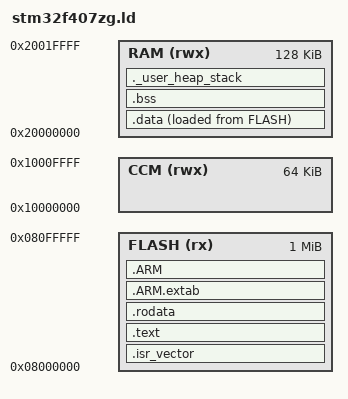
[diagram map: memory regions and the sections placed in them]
/* 仅用于 .simtest 交叉编译验证的链接脚本（STM32F407ZGT6: 1M Flash / 192K RAM） */
ENTRY(Reset_Handler)

MEMORY
{
  FLASH (rx)  : ORIGIN = 0x08000000, LENGTH = 1024K
  RAM   (rwx) : ORIGIN = 0x20000000, LENGTH = 128K
  CCM   (rwx) : ORIGIN = 0x10000000, LENGTH = 64K
}

_estack = ORIGIN(RAM) + LENGTH(RAM);

SECTIONS
{
  .isr_vector : { KEEP(*(.isr_vector)) } > FLASH

  .text :
  {
    *(.text) *(.text*) *(.glue_7) *(.glue_7t) *(.eh_frame)
    KEEP(*(.init)) KEEP(*(.fini))
    . = ALIGN(4);
    _etext = .;
  } > FLASH

  .rodata :
  {
    . = ALIGN(4);
    *(.rodata) *(.rodata*)
    . = ALIGN(4);
  } > FLASH

  .ARM.extab : { *(.ARM.extab*) } > FLASH
  .ARM : { __exidx_start = .; *(.ARM.exidx*) __exidx_end = .; } > FLASH

  _sidata = LOADADDR(.data);

  .data :
  {
    . = ALIGN(4);
    _sdata = .;
    *(.data) *(.data*)
    . = ALIGN(4);
    _edata = .;
  } > RAM AT> FLASH

  .bss :
  {
    . = ALIGN(4);
    _sbss = .;
    __bss_start__ = _sbss;
    *(.bss) *(.bss*) *(COMMON)
    . = ALIGN(4);
    _ebss = .;
    __bss_end__ = _ebss;
    . = ALIGN(8);
    end = .;
    _end = .;
    __end__ = .;
  } > RAM

  ._user_heap_stack :
  {
    . = ALIGN(8);
    . = . + 0x400;
    . = ALIGN(8);
  } > RAM

  /DISCARD/ : { libc.a(*) libm.a(*) libgcc.a(*) }
}
